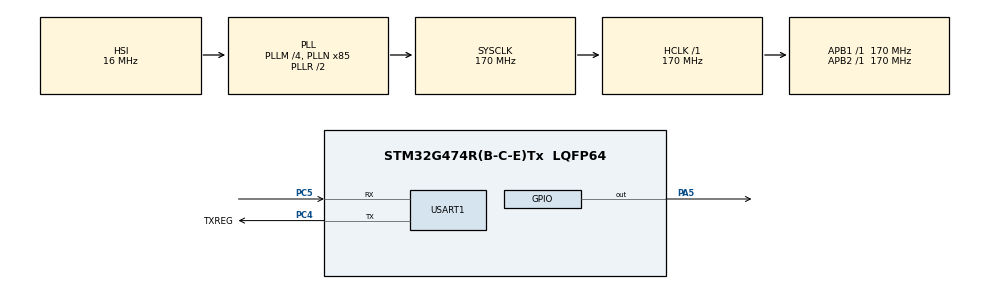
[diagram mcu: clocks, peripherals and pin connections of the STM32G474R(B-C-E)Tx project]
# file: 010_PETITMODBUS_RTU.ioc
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Mcu.Family=STM32G4
Mcu.Name=STM32G474R(B-C-E)Tx
Mcu.Package=LQFP64
NVIC.PriorityGroup=NVIC_PRIORITYGROUP_4
NVIC.TIM1_UP_TIM16_IRQn=true\:0\:0\:false\:false\:true\:true\:true\:true
PA13.Mode=Serial_Wire
PA13.Signal=SYS_JTMS-SWDIO
PA14.Mode=Serial_Wire
PA14.Signal=SYS_JTCK-SWCLK
PA5.Signal=GPIO_Output
PC14-OSC32_IN.Mode=LSE-External-Oscillator
PC14-OSC32_IN.Signal=RCC_OSC32_IN
PC15-OSC32_OUT.Mode=LSE-External-Oscillator
PC15-OSC32_OUT.Signal=RCC_OSC32_OUT
PC4.GPIO_Label=TXREG
PC4.Mode=Asynchronous
PC4.Signal=USART1_TX
PC5.Mode=Asynchronous
PC5.Signal=USART1_RX
PF0-OSC_IN.Mode=HSE-External-Oscillator
PF0-OSC_IN.Signal=RCC_OSC_IN
PF1-OSC_OUT.Mode=HSE-External-Oscillator
PF1-OSC_OUT.Signal=RCC_OSC_OUT
ProjectManager.HeapSize=0x200
ProjectManager.StackSize=0x400
ProjectManager.TargetToolchain=STM32CubeIDE
RCC.ADC12Freq_Value=170000000
RCC.ADC345Freq_Value=170000000
RCC.AHBFreq_Value=170000000
RCC.APB1Freq_Value=170000000
RCC.APB1TimFreq_Value=170000000
RCC.APB2Freq_Value=170000000
RCC.APB2TimFreq_Value=170000000
RCC.CortexFreq_Value=170000000
RCC.EXTERNAL_CLOCK_VALUE=12288000
RCC.HCLKFreq_Value=170000000
RCC.HSE_VALUE=24000000
RCC.HSI48_VALUE=48000000
RCC.HSI_VALUE=16000000
RCC.PLLM=RCC_PLLM_DIV4
RCC.PLLN=85
RCC.RTCClockSelection=RCC_RTCCLKSOURCE_LSE
RCC.SYSCLKFreq_VALUE=170000000
RCC.SYSCLKSource=RCC_SYSCLKSOURCE_PLLCLK
RCC.USBFreq_Value=170000000
RCC.VCOOutputFreq_Value=340000000
TIM1.PeriodNoDither=10
TIM1.Prescaler=1700
USART1.VirtualMode-Asynchronous=VM_ASYNC
VP_SYS_VS_DBSignals.Mode=DisableDeadBatterySignals
VP_TIM16_VS_ClockSourceINT.Mode=Enable_Timer
VP_TIM1_VS_ClockSourceINT.Mode=Internal
board=NUCLEO-G474RE

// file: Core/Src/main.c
/* USER CODE BEGIN Header */
/**
  ******************************************************************************
  * @file           : main.c
  * @brief          : Main program body
  ******************************************************************************
  * @attention
  *
  * Copyright (c) 2024 STMicroelectronics.
  * All rights reserved.
  *
  * This software is licensed under terms that can be found in the LICENSE file
  * in the root directory of this software component.
  * If no LICENSE file comes with this software, it is provided AS-IS.
  *
  ******************************************************************************
  */
/* USER CODE END Header */
#include "main.h"
#include "string.h"

/* USER CODE BEGIN PM */
unsigned char testchar = 'A';
int dongu = 1;
unsigned int PETIT_MODBUS_TIMER_VALUE =0;
unsigned long lastSendTime = 0;
/* USER CODE END PM */

TIM_HandleTypeDef htim1;
TIM_HandleTypeDef htim16;

UART_HandleTypeDef huart1;

void SystemClock_Config(void);
static void MX_GPIO_Init(void);
static void MX_TIM1_Init(void);
static void MX_TIM16_Init(void);
static void MX_USART1_UART_Init(void);

/* USER CODE BEGIN 0 */
void Petit_MODBUS_UART_PUTCH(unsigned char c){

	while (!(huart1.Instance->ISR & USART_ISR_TC)); // TC bayrağı 1 olana kadar çalışacak
	huart1.Instance->TDR = c; // huart1 portunun TDR registerına c yazılacak.

}
void sendTimerValue(void) {
    char buffer[50];
    sprintf(buffer, "SAYİ: %u\n", PETIT_MODBUS_TIMER_VALUE);
    HAL_UART_Transmit(&huart1, (uint8_t*)buffer, strlen(buffer), HAL_MAX_DELAY);
}

/* USER CODE END 0 */

int main(void)
{

  /* MCU Configuration--------------------------------------------------------*/

  /* Reset of all peripherals, Initializes the Flash interface and the Systick. */
  HAL_Init();

  /* Configure the system clock */
  SystemClock_Config();

  /* Initialize all configured peripherals */
  MX_GPIO_Init();
  MX_TIM1_Init();
  MX_TIM16_Init();
  MX_USART1_UART_Init();
  /* USER CODE BEGIN 2 */
  HAL_TIM_Base_Start_IT(&htim16);
  /* USER CODE END 2 */

  /* Infinite loop */
  while (1)
  {

    /* USER CODE BEGIN 3 */

	  Petit_MODBUS_UART_PUTCH(testchar);
	  while(!(huart1.Instance->ISR & USART_ISR_RXNE ));
	  unsigned char reciver = huart1.Instance->RDR;

	  if(reciver == testchar){
		  while(dongu){
		  HAL_GPIO_WritePin(GPIOA, GPIO_PIN_5, GPIO_PIN_SET);
		  HAL_Delay(100);
		  HAL_GPIO_WritePin(GPIOA, GPIO_PIN_5, GPIO_PIN_RESET);
		  HAL_Delay(100);

		  dongu--;
		  }
	  }
	  else {
	      // Hatalı veri alımı durumu
	      HAL_GPIO_WritePin(GPIOA, GPIO_PIN_5, GPIO_PIN_SET);
	      HAL_Delay(1000); // Hata durumunda daha kısa bir yanma süresi
	      HAL_GPIO_WritePin(GPIOA, GPIO_PIN_5, GPIO_PIN_RESET);
	      }

  }
  /* USER CODE END 3 */
}

void SystemClock_Config(void)
{
  RCC_OscInitTypeDef RCC_OscInitStruct = {0};
  RCC_ClkInitTypeDef RCC_ClkInitStruct = {0};

  /** Configure the main internal regulator output voltage
  */
  HAL_PWREx_ControlVoltageScaling(PWR_REGULATOR_VOLTAGE_SCALE1_BOOST);

  /** Initializes the RCC Oscillators according to the specified parameters
  * in the RCC_OscInitTypeDef structure.
  */
  RCC_OscInitStruct.OscillatorType = RCC_OSCILLATORTYPE_HSI;
  RCC_OscInitStruct.HSIState = RCC_HSI_ON;
  RCC_OscInitStruct.HSICalibrationValue = RCC_HSICALIBRATION_DEFAULT;
  RCC_OscInitStruct.PLL.PLLState = RCC_PLL_ON;
  RCC_OscInitStruct.PLL.PLLSource = RCC_PLLSOURCE_HSI;
  RCC_OscInitStruct.PLL.PLLM = RCC_PLLM_DIV4;
  RCC_OscInitStruct.PLL.PLLN = 85;
  RCC_OscInitStruct.PLL.PLLP = RCC_PLLP_DIV2;
  RCC_OscInitStruct.PLL.PLLQ = RCC_PLLQ_DIV2;
  RCC_OscInitStruct.PLL.PLLR = RCC_PLLR_DIV2;
  if (HAL_RCC_OscConfig(&RCC_OscInitStruct) != HAL_OK)
  {
    Error_Handler();
  }

  /** Initializes the CPU, AHB and APB buses clocks
  */
  RCC_ClkInitStruct.ClockType = RCC_CLOCKTYPE_HCLK|RCC_CLOCKTYPE_SYSCLK
                              |RCC_CLOCKTYPE_PCLK1|RCC_CLOCKTYPE_PCLK2;
  RCC_ClkInitStruct.SYSCLKSource = RCC_SYSCLKSOURCE_PLLCLK;
  RCC_ClkInitStruct.AHBCLKDivider = RCC_SYSCLK_DIV1;
  RCC_ClkInitStruct.APB1CLKDivider = RCC_HCLK_DIV1;
  RCC_ClkInitStruct.APB2CLKDivider = RCC_HCLK_DIV1;

  if (HAL_RCC_ClockConfig(&RCC_ClkInitStruct, FLASH_LATENCY_4) != HAL_OK)
  {
    Error_Handler();
  }
}

static void MX_TIM1_Init(void)
{

  TIM_ClockConfigTypeDef sClockSourceConfig = {0};
  TIM_MasterConfigTypeDef sMasterConfig = {0};

  htim1.Instance = TIM1;
  htim1.Init.Prescaler = 1700;
  htim1.Init.CounterMode = TIM_COUNTERMODE_UP;
  htim1.Init.Period = 10;
  htim1.Init.ClockDivision = TIM_CLOCKDIVISION_DIV1;
  htim1.Init.RepetitionCounter = 0;
  htim1.Init.AutoReloadPreload = TIM_AUTORELOAD_PRELOAD_DISABLE;
  if (HAL_TIM_Base_Init(&htim1) != HAL_OK)
  {
    Error_Handler();
  }
  sClockSourceConfig.ClockSource = TIM_CLOCKSOURCE_INTERNAL;
  if (HAL_TIM_ConfigClockSource(&htim1, &sClockSourceConfig) != HAL_OK)
  {
    Error_Handler();
  }
  sMasterConfig.MasterOutputTrigger = TIM_TRGO_RESET;
  sMasterConfig.MasterOutputTrigger2 = TIM_TRGO2_RESET;
  sMasterConfig.MasterSlaveMode = TIM_MASTERSLAVEMODE_DISABLE;
  if (HAL_TIMEx_MasterConfigSynchronization(&htim1, &sMasterConfig) != HAL_OK)
  {
    Error_Handler();
  }

}

static void MX_TIM16_Init(void)
{

  htim16.Instance = TIM16;
  htim16.Init.Prescaler = 0;
  htim16.Init.CounterMode = TIM_COUNTERMODE_UP;
  htim16.Init.Period = 65535;
  htim16.Init.ClockDivision = TIM_CLOCKDIVISION_DIV1;
  htim16.Init.RepetitionCounter = 0;
  htim16.Init.AutoReloadPreload = TIM_AUTORELOAD_PRELOAD_DISABLE;
  if (HAL_TIM_Base_Init(&htim16) != HAL_OK)
  {
    Error_Handler();
  }

}

static void MX_USART1_UART_Init(void)
{

  huart1.Instance = USART1;
  huart1.Init.BaudRate = 115200;
  huart1.Init.WordLength = UART_WORDLENGTH_8B;
  huart1.Init.StopBits = UART_STOPBITS_1;
  huart1.Init.Parity = UART_PARITY_NONE;
  huart1.Init.Mode = UART_MODE_TX_RX;
  huart1.Init.HwFlowCtl = UART_HWCONTROL_NONE;
  huart1.Init.OverSampling = UART_OVERSAMPLING_16;
  huart1.Init.OneBitSampling = UART_ONE_BIT_SAMPLE_DISABLE;
  huart1.Init.ClockPrescaler = UART_PRESCALER_DIV1;
  huart1.AdvancedInit.AdvFeatureInit = UART_ADVFEATURE_NO_INIT;
  if (HAL_UART_Init(&huart1) != HAL_OK)
  {
    Error_Handler();
  }
  if (HAL_UARTEx_SetTxFifoThreshold(&huart1, UART_TXFIFO_THRESHOLD_1_8) != HAL_OK)
  {
    Error_Handler();
  }
  if (HAL_UARTEx_SetRxFifoThreshold(&huart1, UART_RXFIFO_THRESHOLD_1_8) != HAL_OK)
  {
    Error_Handler();
  }
  if (HAL_UARTEx_DisableFifoMode(&huart1) != HAL_OK)
  {
    Error_Handler();
  }

}

static void MX_GPIO_Init(void)
{
  GPIO_InitTypeDef GPIO_InitStruct = {0};

  /* GPIO Ports Clock Enable */
  __HAL_RCC_GPIOC_CLK_ENABLE();
  __HAL_RCC_GPIOF_CLK_ENABLE();
  __HAL_RCC_GPIOA_CLK_ENABLE();

  /*Configure GPIO pin Output Level */
  HAL_GPIO_WritePin(GPIOA, GPIO_PIN_5, GPIO_PIN_RESET);

  /*Configure GPIO pin : PA5 */
  GPIO_InitStruct.Pin = GPIO_PIN_5;
  GPIO_InitStruct.Mode = GPIO_MODE_OUTPUT_PP;
  GPIO_InitStruct.Pull = GPIO_NOPULL;
  GPIO_InitStruct.Speed = GPIO_SPEED_FREQ_LOW;
  HAL_GPIO_Init(GPIOA, &GPIO_InitStruct);

}

/* USER CODE BEGIN 4 */
void HAL_TIM_PeriodElapsedCallback(TIM_HandleTypeDef *htim){
	PETIT_MODBUS_TIMER_VALUE++;
	dongu++;

}

/* USER CODE END 4 */

void Error_Handler(void)
{
  __disable_irq();
  while (1)
  {
  }
}
